# STM32G0B0xx register map
File version: 1.0
Registers are 32-bit, read-write, reset 0x0 unless marked. A register's access mark holds for its fields unless they carry their own. Offsets are from the block's base; [hi:lo] are bit positions; {n}, {i} and the like mark numbered series.

## WWDG — Window WATCHDOG
Base 0x40002C00
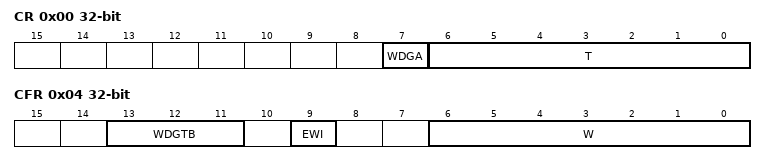
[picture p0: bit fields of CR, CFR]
0x00 CR — WWDG Control register
  [7] WDGA — Activation bit
  [6:0] T — T[6:0] bits (7-Bit counter (MSB to LSB))
0x04 CFR — WWDG Configuration register
  [13:11] WDGTB — WDGTB[2:0] bits (Timer Base)
    0=PRESCALER_1 (WWDG counter clock = (PCLK1/4096)/1); 1=PRESCALER_2 (WWDG counter clock = (PCLK1/4096)/2); 2=PRESCALER_4 (WWDG counter clock = (PCLK1/4096)/4); 3=PRESCALER_8 (WWDG counter clock = (PCLK1/4096)/8); 4=PRESCALER_16 (WWDG counter clock = (PCLK1/4096)/16); 5=PRESCALER_32 (WWDG counter clock = (PCLK1/4096)/32); 6=PRESCALER_64 (WWDG counter clock = (PCLK1/4096)/64); 7=PRESCALER_128 (WWDG counter clock = (PCLK1/4096)/128)
  [9] EWI — Early Wakeup Interrupt
  [6:0] W — W[6:0] bits (7-bit window value)
0x08 SR — WWDG Status register
  [0] EWIF — Early Wakeup Interrupt Flag

## IWDG — Independent WATCHDOG
Base 0x40003000
0x00 KR — IWDG Key register
  [15:0] KEY — Key value (write only, read 0000h)
0x04 PR — IWDG Prescaler register
  [2:0] PR — PR[2:0] (Prescaler divider)
0x08 RLR — IWDG Reload register
  [11:0] RL — Watchdog counter reload value
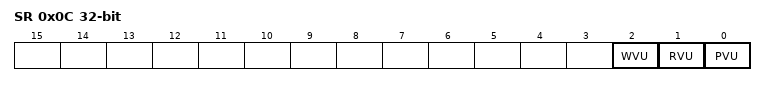
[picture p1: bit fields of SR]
0x0C SR — IWDG Status register
  [2] WVU — Watchdog counter window value update
  [1] RVU — Watchdog counter reload value update
  [0] PVU — Watchdog prescaler value update
0x10 WINR — IWDG Window register
  [11:0] WIN — Watchdog counter window value

## USB_DRD_FS — Universal Serial Bus Full Speed Dual Role Device
Base 0x40005C00
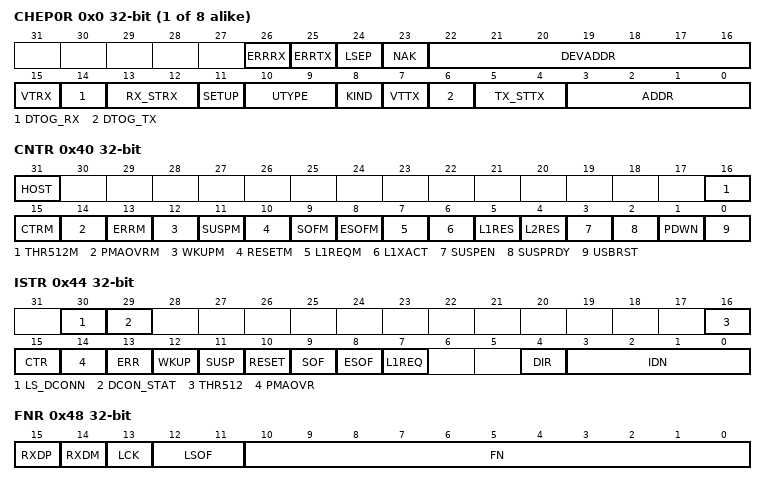
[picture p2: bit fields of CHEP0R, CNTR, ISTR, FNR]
{0x0+4i} CHEP{i}R (i=0..7) — USB Channel/Endpoint {i} register
  [26] ERRRX — Receive error
  [25] ERRTX — Transmit error
  [24] LSEP — Low Speed Endpoint (host with Hub Only)
  [23] NAK — Previous NAK detected
  [22:16] DEVADDR
  [15] VTRX — USB valid transaction received Mask
  [14] DTOG_RX — Data Toggle, for reception transfers Mask
  [13:12] RX_STRX — Status bits, for reception transfers Mask
  [11] SETUP — Setup transaction completed Mask
  [10:9] UTYPE — USB type of transaction Mask
  [8] KIND — EndPoint KIND Mask
  [7] VTTX — Valid USB transaction transmitted Mask
  [6] DTOG_TX — Data Toggle, for transmission transfers Mask
  [5:4] TX_STTX — Status bits, for transmission transfers Mask
  [3:0] ADDR — Endpoint address Mask
0x40 CNTR — Control register
  [31] HOST — Host Mode
  [16] THR512M — 512byte Threshold interrupt mask
  [15] CTRM — Correct Transfer Mask
  [14] PMAOVRM — DMA OVeR/underrun Mask
  [13] ERRM — ERRor Mask
  [12] WKUPM — WaKe UP Mask
  [11] SUSPM — SUSPend Mask
  [10] RESETM — RESET Mask
  [9] SOFM — Start Of Frame Mask
  [8] ESOFM — Expected Start Of Frame Mask
  [7] L1REQM — LPM L1 state request interrupt Mask
  [6] L1XACT — Host LPM L1 transaction request Mask
  [5] L1RES — LPM L1 Resume request/ Remote Wakeup Mask
  [4] L2RES — L2 Remote Wakeup / Resume driver Mask
  [3] SUSPEN — Suspend state enable Mask
  [2] SUSPRDY — Suspend state effective Mask
  [1] PDWN — Power DoWN Mask
  [0] USBRST — USB Reset Mask
0x44 ISTR — Interrupt status register
  [30] LS_DCONN — LS_DCONN Mask
  [29] DCON_STAT — Device Connection status (connected/Disconnected) don't cause an interrupt
  [16] THR512 — 512byte threshold interrupt (used with isochrnous single buffer )
  [15] CTR — Correct TRansfer (clear-only bit) Mask
  [14] PMAOVR — PMA OVeR/underrun (clear-only bit) Mask
  [13] ERR — ERRor (clear-only bit) Mask
  [12] WKUP — WaKe UP (clear-only bit) Mask
  [11] SUSP — SUSPend (clear-only bit) Mask
  [10] RESET — RESET Mask
  [9] SOF — Start Of Frame (clear-only bit) Mask
  [8] ESOF — Expected Start Of Frame (clear-only bit) Mask
  [7] L1REQ — LPM L1 state request Mask
  [4] DIR — DIRection of transaction (read-only bit) Mask
  [3:0] IDN — EndPoint IDentifier (read-only bit) Mask
0x48 FNR — Frame number register
  [15] RXDP — status of D+ data line Mask
  [14] RXDM — status of D- data line Mask
  [13] LCK — LoCKed Mask
  [12:11] LSOF — Lost SOF Mask
  [10:0] FN — Frame Number Mask
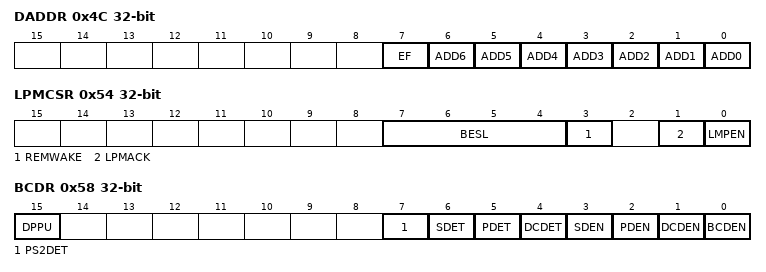
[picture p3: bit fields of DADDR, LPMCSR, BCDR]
0x4C DADDR — Device address register
  [7] EF — Enable Function Mask
  [n] ADD{n} (n=0..6) — Bit {n} Mask
0x54 LPMCSR — LPM Control and Status register
  [7:4] BESL — BESL value received with last ACKed LPM Token Mask
  [3] REMWAKE — bRemoteWake value received with last ACKed LPM Token Mask
  [1] LPMACK — LPM Token acknowledge enable Mask
  [0] LMPEN — LPM support enable Mask
0x58 BCDR — Battery Charging detector register
  [15] DPPU — DP Pull-up Enable Mask
  [7] PS2DET — PS2 port or proprietary charger detected Mask
  [6] SDET — Secondary detection (SD) status Mask
  [5] PDET — Primary detection (PD) status Mask
  [4] DCDET — Data contact detection (DCD) status Mask
  [3] SDEN — Secondary detection (SD) mode enable Mask
  [2] PDEN — Primary detection (PD) mode enable Mask
  [1] DCDEN — Data contact detection (DCD) mode enable Mask
  [0] BCDEN — Battery charging detector (BCD) enable Mask
